# STM32H7R3xx register map
File version: 1.0
Registers are 32-bit, read-write, reset 0x0 unless marked. A register's access mark holds for its fields unless they carry their own. Offsets are from the block's base; [hi:lo] are bit positions; {n}, {i} and the like mark numbered series.

## EXTI — External Interrupt/Event Controller
Base 0x58000000
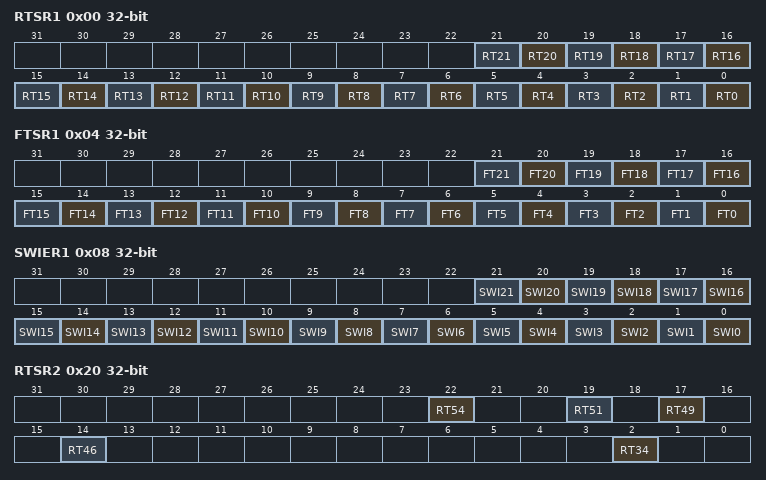
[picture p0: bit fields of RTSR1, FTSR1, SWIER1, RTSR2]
0x00 RTSR1 — EXTI Rising trigger selection register 1
  [n] RT{n} (n=0..21) — Rising trigger configuration for input line {n}
0x04 FTSR1 — EXTI Falling trigger selection register 1
  [n] FT{n} (n=0..21) — Falling trigger configuration for input line {n}
0x08 SWIER1 — EXTI Software interrupt event register 1
  [n] SWI{n} (n=0..21) — Software Interrupt on line {n}
0x20 RTSR2 — EXTI Rising trigger selection register 2
  [22] RT54 — Rising trigger configuration for input line 54
  [19] RT51 — Rising trigger configuration for input line 51
  [17] RT49 — Rising trigger configuration for input line 49
  [14] RT46 — Rising trigger configuration for input line 46
  [2] RT34 — Rising trigger configuration for input line 34
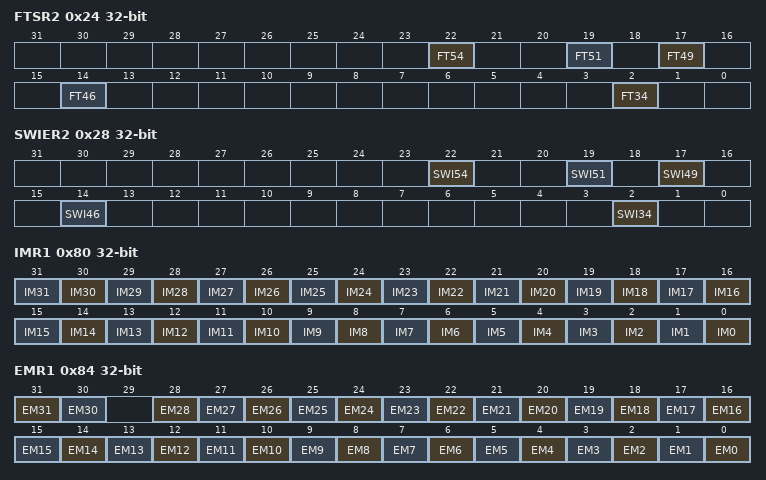
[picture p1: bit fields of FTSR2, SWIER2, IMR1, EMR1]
0x24 FTSR2 — EXTI Falling trigger selection register 2
  [22] FT54 — Falling trigger configuration for input line 54
  [19] FT51 — Falling trigger configuration for input line 51
  [17] FT49 — Falling trigger configuration for input line 49
  [14] FT46 — Falling trigger configuration for input line 46
  [2] FT34 — Falling trigger configuration for input line 34
0x28 SWIER2 — EXTI Software interrupt event register 2
  [22] SWI54 — Software Interrupt on line 54
  [19] SWI51 — Software Interrupt on line 51
  [17] SWI49 — Software Interrupt on line 49
  [14] SWI46 — Software Interrupt on line 46
  [2] SWI34 — Software Interrupt on line 34
0x80 IMR1 — EXTI Interrupt mask register 1
  [n] IM{n} (n=0..31) — Interrupt Mask on line {n}
0x84 EMR1 — EXTI Event mask register 1
  [31] EM31 — Event Mask on line 31
  [30] EM30 — Event Mask on line 30
  [n] EM{n} (n=0..28) — Event Mask on line {n}
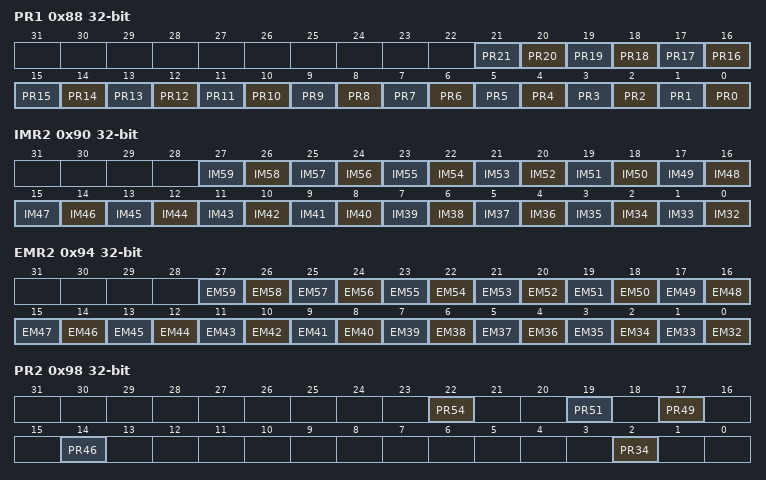
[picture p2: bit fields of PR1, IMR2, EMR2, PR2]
0x88 PR1 — EXTI Pending register 1
  [n] PR{n} (n=0..21) — Pending bit for line {n}
0x90 IMR2 — EXTI Interrupt mask register 2
  [n-32] IM{n} (n=32..59) — Interrupt Mask on line {n}
0x94 EMR2 — EXTI Event mask register 2
  [n-32] EM{n} (n=32..59) — Event Mask on line {n}
0x98 PR2 — EXTI Pending register 2
  [22] PR54 — Event Mask on line 54
  [19] PR51 — Event Mask on line 51
  [17] PR49 — Event Mask on line 49
  [14] PR46 — Event Mask on line 46
  [2] PR34 — Event Mask on line 34
0xA0 IMR3 — EXTI Interrupt mask register 3
  [13] IM77 — Interrupt Mask on line 77
0xA4 EMR3 — EXTI Event mask register 3
  [13] EM77 — Event Mask on line 77

## VREFBUF
Base 0x58003C00
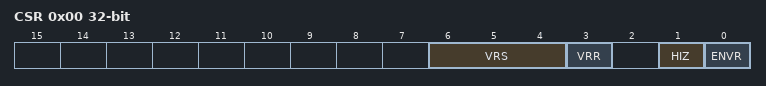
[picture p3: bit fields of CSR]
0x00 CSR — VREFBUF control and status register
  [6:4] VRS — Voltage reference scale
    {v}=SCALE{v} (Voltage reference scale {v} (VREF_OUT{v+1})) (v=0..3)
  [3] VRR — Voltage reference buffer ready
  [1] HIZ — High impedance mode
  [0] ENVR — Voltage reference buffer enable
0x04 CCR — VREFBUF calibration and control register
  [5:0] TRIM — TRIM[5:0] bits (Trimming code)

## TAMP — Tamper and backup registers
Base 0x58004400
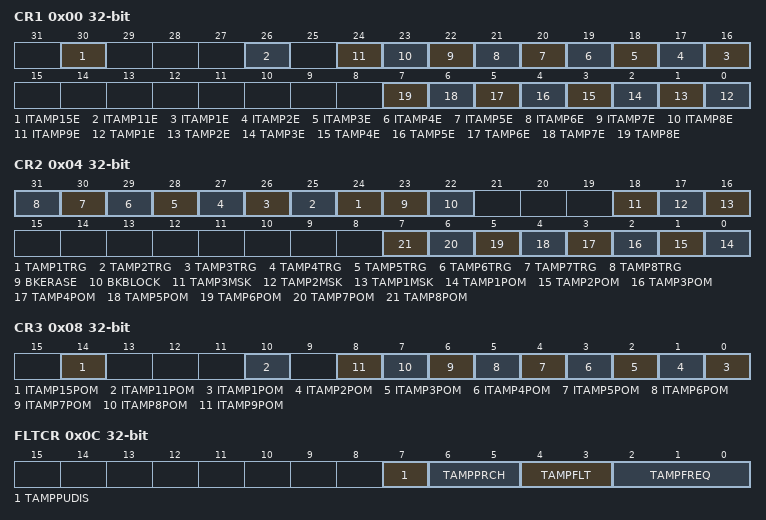
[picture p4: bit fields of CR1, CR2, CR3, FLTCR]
0x00 CR1 — TAMP configuration register 1
  [30] ITAMP15E, [26] ITAMP11E, [n+15] ITAMP{n}E (n=1..9), [n-1] TAMP{n}E (n=1..8)
0x04 CR2 — TAMP configuration register 2
  [n+23] TAMP{n}TRG (n=1..8), [23] BKERASE, [22] BKBLOCK, [18] TAMP3MSK, [17] TAMP2MSK, [16] TAMP1MSK, [n-1] TAMP{n}POM (n=1..8)
0x08 CR3 — TAMP configuration register 3
  [14] ITAMP15POM, [10] ITAMP11POM, [n-1] ITAMP{n}POM (n=1..9)
0x0C FLTCR — TAMP filter control register
  [7] TAMPPUDIS
  [6:5] TAMPPRCH
    0=DURATION_1RTCCLK (Tamper pins are pre-charged before sampling during 1 RTCCLK cycle); 1=DURATION_2RTCCLK (Tamper pins are pre-charged before sampling during 2 RTCCLK cycles); 2=DURATION_4RTCCLK (Tamper pins are pre-charged before sampling during 4 RTCCLK cycles); 3=DURATION_8RTCCLK (Tamper pins are pre-charged before sampling during 8 RTCCLK cycles)
  [4:3] TAMPFLT
    0=DISABLE (Tamper filter is disabled); 1=FILTER_2SAMPLE (Tamper is activated after 2 consecutive samples at the active level); 2=FILTER_4SAMPLE (Tamper is activated after 4 consecutive samples at the active level); 3=FILTER_8SAMPLE (Tamper is activated after 8 consecutive samples at the active level)
  [2:0] TAMPFREQ
    0=SAMPLFREQDIV_32768 (Each of the tamper inputs are sampled with a frequency = RTCCLK / 32768); 1=SAMPLFREQDIV_16384 (Each of the tamper inputs are sampled with a frequency = RTCCLK / 16384); 2=SAMPLFREQDIV_8192 (Each of the tamper inputs are sampled with a frequency = RTCCLK / 8192); 3=SAMPLFREQDIV_4096 (Each of the tamper inputs are sampled with a frequency = RTCCLK / 4096); 4=SAMPLFREQDIV_2048 (Each of the tamper inputs are sampled with a frequency = RTCCLK / 2048); 5=SAMPLFREQDIV_1024 (Each of the tamper inputs are sampled with a frequency = RTCCLK / 1024); 6=SAMPLFREQDIV_512 (Each of the tamper inputs are sampled with a frequency = RTCCLK / 512); 7=SAMPLFREQDIV_256 (Each of the tamper inputs are sampled with a frequency = RTCCLK / 256)
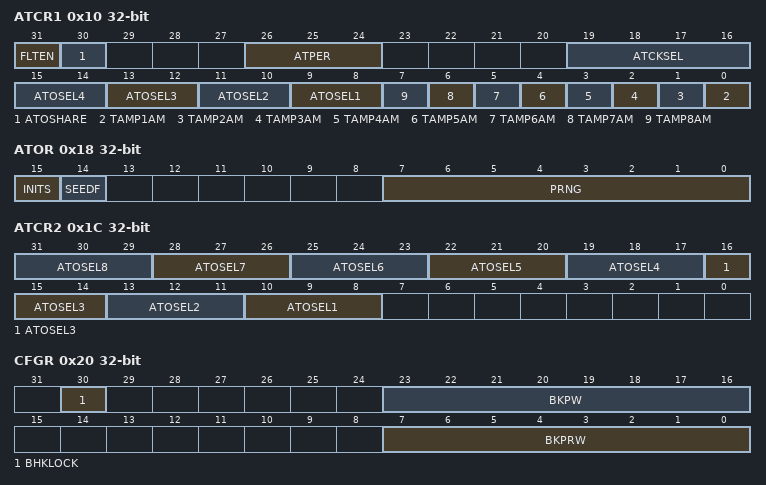
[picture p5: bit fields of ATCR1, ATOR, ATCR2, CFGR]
0x10 ATCR1 — TAMP filter control register 1
  [31] FLTEN, [30] ATOSHARE, [26:24] ATPER, [19:16] ATCKSEL, [2n+7:2n+6] ATOSEL{n} (n=1..4), [n-1] TAMP{n}AM (n=1..8)
0x14 ATSEEDR — TAMP active tamper seed register
  [31:0] SEED
0x18 ATOR — TAMP active tamper output register
  [15] INITS, [14] SEEDF, [7:0] PRNG
0x1C ATCR2 — TAMP filter control register 2
  [3n+7:3n+5] ATOSEL{n} (n=1..8)
0x20 CFGR — TAMP configuration control register
  [30] BHKLOCK, [23:16] BKPW, [7:0] BKPRW
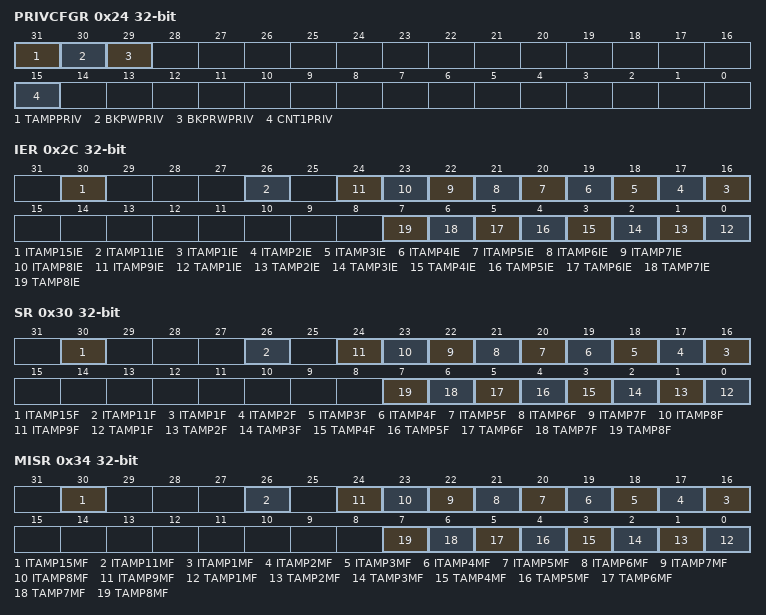
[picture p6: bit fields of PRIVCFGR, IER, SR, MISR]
0x24 PRIVCFGR — TAMP privilege mode control register
  [31] TAMPPRIV
    1=YES (TAMP full privilege); 0=NO (TAMP is not privilege)
  [30] BKPWPRIV
  [29] BKPRWPRIV
  [15] CNT1PRIV
0x2C IER — TAMP interrupt enable register
  [30] ITAMP15IE, [26] ITAMP11IE, [n+15] ITAMP{n}IE (n=1..9), [n-1] TAMP{n}IE (n=1..8)
0x30 SR — TAMP status register
  [30] ITAMP15F, [26] ITAMP11F, [n+15] ITAMP{n}F (n=1..9), [n-1] TAMP{n}F (n=1..8)
0x34 MISR — TAMP masked interrupt status register
  [30] ITAMP15MF, [26] ITAMP11MF, [n+15] ITAMP{n}MF (n=1..9), [n-1] TAMP{n}MF (n=1..8)
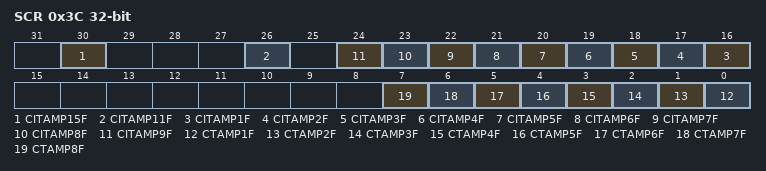
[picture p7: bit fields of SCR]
0x3C SCR — TAMP status clear register
  [30] CITAMP15F, [26] CITAMP11F, [n+15] CITAMP{n}F (n=1..9), [n-1] CTAMP{n}F (n=1..8)
0x40 COUNT1R — TAMP monotonic counter 1 register
  [31:0] COUNT
0x54 RPCFGR — TAMP resources protection configuration register
  [0] RPCFG0
{0x100+4i} BKP{i}R (i=0..31) — TAMP backup register {i}
